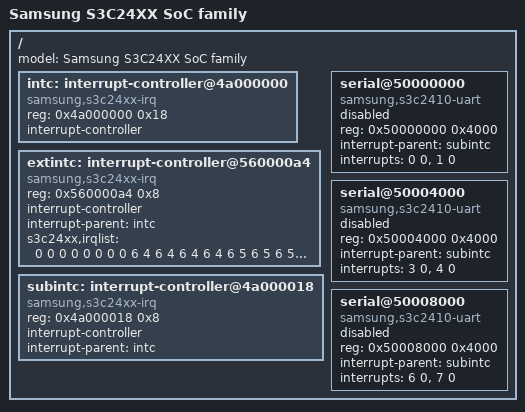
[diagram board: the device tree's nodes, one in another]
/*
 * Samsung's S3C2416 SoC device tree source
 *
 * Copyright (c) 2012 Heiko Stuebner <heiko@sntech.de>
 *
 * This program is free software; you can redistribute it and/or modify
 * it under the terms of the GNU General Public License version 2 as
 * published by the Free Software Foundation.
*/

/include/ "skeleton.dtsi"

/ {
	model = "Samsung S3C24XX SoC family";

	intc:interrupt-controller@4a000000 {
		compatible = "samsung,s3c24xx-irq";
		reg = <0x4a000000 0x18>;
		interrupt-controller;
		#interrupt-cells = <2>;
	};

	extintc:interrupt-controller@560000a4 {
		compatible = "samsung,s3c24xx-irq";
		reg = <0x560000a4 0x8>;
		interrupt-controller;
		interrupt-parent = <&intc>;
		#interrupt-cells = <2>;

		s3c24xx,irqlist = <0 0 /* reserved */
				   0 0 /* reserved */
				   0 0 /* reserved */
				   0 0 /* reserved */
				   6 4 /* EINT4 */
				   6 4 /* EINT5 */
				   6 4 /* EINT6 */
				   6 4 /* EINT7 */
				   6 5 /* EINT8 */
				   6 5 /* EINT9 */
				   6 5 /* EINT10 */
				   6 5 /* EINT11 */
				   6 5 /* EINT12 */
				   6 5 /* EINT13 */
				   6 5 /* EINT14 */
				   6 5 /* EINT15 */
				   6 5 /* EINT16 */
				   6 5 /* EINT17 */
				   6 5 /* EINT18 */
				   6 5 /* EINT19 */
				   6 5 /* EINT20 */
				   6 5 /* EINT21 */
				   6 5 /* EINT22 */
				   6 5>; /* EINT23 */
	};

	subintc:interrupt-controller@4a000018 {
		compatible = "samsung,s3c24xx-irq";
		reg = <0x4a000018 0x8>;
		interrupt-controller;
		interrupt-parent = <&intc>;
		#interrupt-cells = <2>;
	};

	serial@50000000 {
		compatible = "samsung,s3c2410-uart";
		reg = <0x50000000 0x4000>;
		interrupt-parent = <&subintc>;
		interrupts = <0 0>, <1 0>;
		status = "disabled";
	};

	serial@50004000 {
		compatible = "samsung,s3c2410-uart";
		reg = <0x50004000 0x4000>;
		interrupt-parent = <&subintc>;
		interrupts = <3 0>, <4 0>;
		status = "disabled";
	};

	serial@50008000 {
		compatible = "samsung,s3c2410-uart";
		reg = <0x50008000 0x4000>;
		interrupt-parent = <&subintc>;
		interrupts = <6 0>, <7 0>;
		status = "disabled";
	};
};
